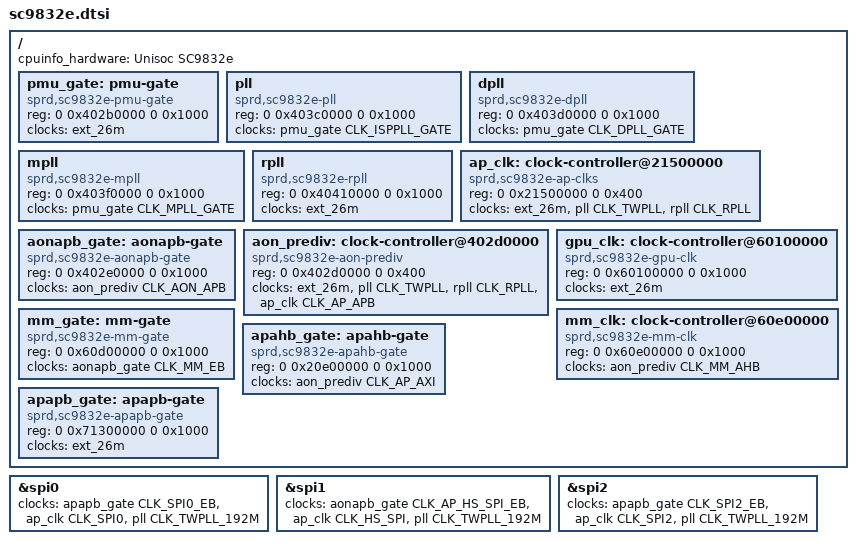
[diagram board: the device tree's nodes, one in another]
/*
 * Spreadtrum SC9832e SoC DTS file
 *
 * Copyright (C) 2018, Spreadtrum Communications Inc.
 *
 * SPDX-License-Identifier: (GPL-2.0+ OR MIT)
 */

#include "sharkle.dtsi"

/ {
	cpuinfo_hardware = "Unisoc SC9832e";
	pmu_gate: pmu-gate {
		compatible = "sprd,sc9832e-pmu-gate";
		/*sprd,syscon = <&pmu_apb_regs>;*/ /* 0x402b0000 */
		reg = <0 0x402b0000 0 0x1000>;
		clocks = <&ext_26m>;
		#clock-cells = <1>;
	};

	pll: pll {
		compatible = "sprd,sc9832e-pll";
		/*sprd,syscon = <&anlg_phy_g1_regs>;*/ /* 0x403c0000 */
		reg = <0 0x403c0000 0 0x1000>;
		clocks = <&pmu_gate CLK_ISPPLL_GATE>;
		#clock-cells = <1>;
	};

	dpll: dpll {
		compatible = "sprd,sc9832e-dpll";
		/*sprd,syscon = <&anlg_phy_g2_regs>;*/ /* 0x403d0000 */
		reg = <0 0x403d0000 0 0x1000>;
		clocks = <&pmu_gate CLK_DPLL_GATE>;
		#clock-cells = <1>;
	};

	mpll: mpll {
		compatible = "sprd,sc9832e-mpll";
		/*sprd,syscon = <&anlg_phy_g4_regs>;*/ /* 0x403f0000 */
		reg = <0 0x403f0000 0 0x1000>;
		clocks = <&pmu_gate CLK_MPLL_GATE>;
		#clock-cells = <1>;
	};

	rpll: rpll {
		compatible = "sprd,sc9832e-rpll";
		/*sprd,syscon = <&anlg_phy_g6_regs>;*/ /* 0x40410000 */
		reg = <0 0x40410000 0 0x1000>;
		clocks = <&ext_26m>;
		#clock-cells = <1>;
	};

	ap_clk: clock-controller@21500000 {
		compatible = "sprd,sc9832e-ap-clks";
		reg = <0 0x21500000 0 0x400>;
		clocks = <&ext_26m>, <&pll CLK_TWPLL>,
			 <&rpll CLK_RPLL>;
		#clock-cells = <1>;
	};

	aonapb_gate: aonapb-gate {
		compatible = "sprd,sc9832e-aonapb-gate"; /* 0x402e0000 */
		/*sprd,syscon = <&aon_apb_regs>;*/
		reg = <0 0x402e0000 0 0x1000>;
		clocks = <&aon_prediv CLK_AON_APB>;
		#clock-cells = <1>;
	};

	aon_prediv: clock-controller@402d0000 {
		compatible = "sprd,sc9832e-aon-prediv";
		reg = <0 0x402d0000 0 0x400>;
		clocks = <&ext_26m>, <&pll CLK_TWPLL>,
			 <&rpll CLK_RPLL>, <&ap_clk CLK_AP_APB>;
		#clock-cells = <1>;
	};

	gpu_clk: clock-controller@60100000 {
		compatible = "sprd,sc9832e-gpu-clk";
		reg = <0 0x60100000 0 0x1000>; /* 0x60100000 */
		clocks = <&ext_26m>;
		#clock-cells = <1>;
	};

	mm_gate: mm-gate {
		compatible = "sprd,sc9832e-mm-gate";
		/*sprd,syscon = <&mm_ahb_regs>;*/ /* 0x60d00000 */
		reg = <0 0x60d00000 0 0x1000>;
		clocks = <&aonapb_gate CLK_MM_EB>;
		#clock-cells = <1>;
	};

	mm_clk: clock-controller@60e00000 {
		compatible = "sprd,sc9832e-mm-clk";
		reg = <0 0x60e00000 0 0x1000>; /* 0x60e00000 */
		clocks = <&aon_prediv CLK_MM_AHB>;
		#clock-cells = <1>;
	};

	apahb_gate: apahb-gate {
		compatible = "sprd,sc9832e-apahb-gate";
		/*sprd,syscon = <&ap_ahb_regs>;*/ /* 0x20e00000 */
		reg = <0 0x20e00000 0 0x1000>;
		clocks = <&aon_prediv CLK_AP_AXI>;
		#clock-cells = <1>;
	};

	apapb_gate: apapb-gate {
		compatible = "sprd,sc9832e-apapb-gate";
		/*sprd,syscon = <&ap_apb_regs>;*/ /* 0x71300000 */
		reg = <0 0x71300000 0 0x1000>;
		clocks = <&ext_26m>;
		#clock-cells = <1>;
	};
};

&spi0 {
	clock-names = "enable", "spi", "source";
	clocks = <&apapb_gate CLK_SPI0_EB>,
	<&ap_clk CLK_SPI0>, <&pll CLK_TWPLL_192M>;
};

&spi1 {
	clock-names = "enable", "spi", "source";
	clocks = <&aonapb_gate CLK_AP_HS_SPI_EB>,
	<&ap_clk CLK_HS_SPI>, <&pll CLK_TWPLL_192M>;
};

&spi2 {
	clock-names = "enable", "spi", "source";
	clocks = <&apapb_gate CLK_SPI2_EB>,
	<&ap_clk CLK_SPI2>, <&pll CLK_TWPLL_192M>;
};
